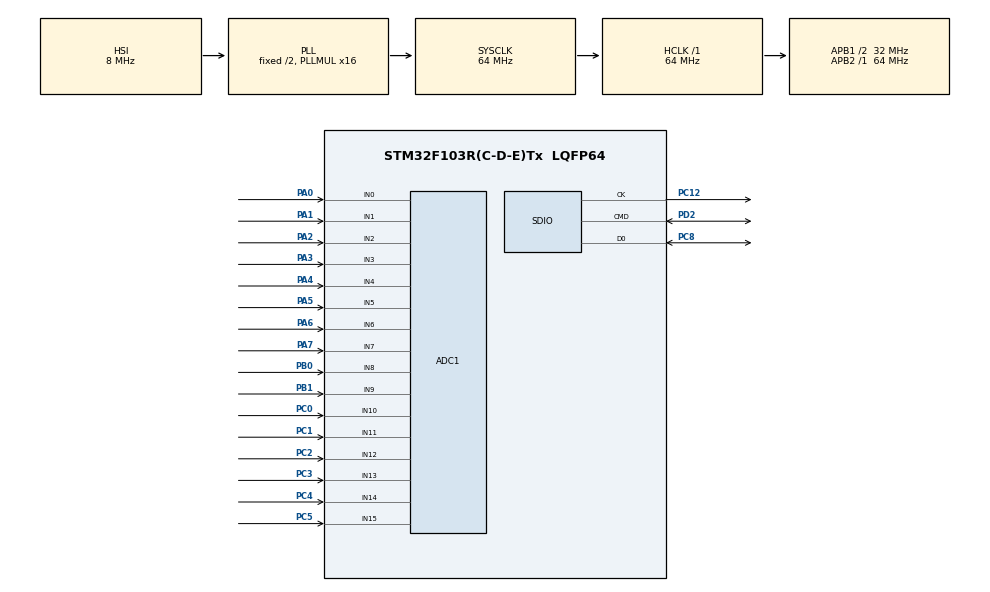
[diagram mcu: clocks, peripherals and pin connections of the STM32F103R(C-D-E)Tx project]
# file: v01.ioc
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ADC1.Channel-0\#ChannelRegularConversion=ADC_CHANNEL_0
ADC1.Channel-10\#ChannelRegularConversion=ADC_CHANNEL_6
ADC1.Channel-11\#ChannelRegularConversion=ADC_CHANNEL_7
ADC1.Channel-12\#ChannelRegularConversion=ADC_CHANNEL_8
ADC1.Channel-13\#ChannelRegularConversion=ADC_CHANNEL_9
ADC1.Channel-14\#ChannelRegularConversion=ADC_CHANNEL_10
ADC1.Channel-15\#ChannelRegularConversion=ADC_CHANNEL_11
ADC1.Channel-16\#ChannelRegularConversion=ADC_CHANNEL_12
ADC1.Channel-17\#ChannelRegularConversion=ADC_CHANNEL_13
ADC1.Channel-18\#ChannelRegularConversion=ADC_CHANNEL_14
ADC1.Channel-19\#ChannelRegularConversion=ADC_CHANNEL_15
ADC1.Channel-5\#ChannelRegularConversion=ADC_CHANNEL_1
ADC1.Channel-6\#ChannelRegularConversion=ADC_CHANNEL_2
ADC1.Channel-7\#ChannelRegularConversion=ADC_CHANNEL_3
ADC1.Channel-8\#ChannelRegularConversion=ADC_CHANNEL_4
ADC1.Channel-9\#ChannelRegularConversion=ADC_CHANNEL_5
ADC1.ContinuousConvMode=ENABLE
ADC1.InjNumberOfConversion=0
ADC1.NbrOfConversion=16
ADC1.NbrOfConversionFlag=1
ADC1.Rank-0\#ChannelRegularConversion=1
ADC1.Rank-10\#ChannelRegularConversion=7
ADC1.Rank-11\#ChannelRegularConversion=8
ADC1.Rank-12\#ChannelRegularConversion=9
ADC1.Rank-13\#ChannelRegularConversion=10
ADC1.Rank-14\#ChannelRegularConversion=11
ADC1.Rank-15\#ChannelRegularConversion=12
ADC1.Rank-16\#ChannelRegularConversion=13
ADC1.Rank-17\#ChannelRegularConversion=14
ADC1.Rank-18\#ChannelRegularConversion=15
ADC1.Rank-19\#ChannelRegularConversion=16
ADC1.Rank-5\#ChannelRegularConversion=2
ADC1.Rank-6\#ChannelRegularConversion=3
ADC1.Rank-7\#ChannelRegularConversion=4
ADC1.Rank-8\#ChannelRegularConversion=5
ADC1.Rank-9\#ChannelRegularConversion=6
ADC1.SamplingTime-0\#ChannelRegularConversion=ADC_SAMPLETIME_1CYCLE_5
ADC1.SamplingTime-10\#ChannelRegularConversion=ADC_SAMPLETIME_1CYCLE_5
ADC1.SamplingTime-11\#ChannelRegularConversion=ADC_SAMPLETIME_1CYCLE_5
ADC1.SamplingTime-12\#ChannelRegularConversion=ADC_SAMPLETIME_1CYCLE_5
ADC1.SamplingTime-13\#ChannelRegularConversion=ADC_SAMPLETIME_1CYCLE_5
ADC1.SamplingTime-14\#ChannelRegularConversion=ADC_SAMPLETIME_1CYCLE_5
ADC1.SamplingTime-15\#ChannelRegularConversion=ADC_SAMPLETIME_1CYCLE_5
ADC1.SamplingTime-16\#ChannelRegularConversion=ADC_SAMPLETIME_1CYCLE_5
ADC1.SamplingTime-17\#ChannelRegularConversion=ADC_SAMPLETIME_1CYCLE_5
ADC1.SamplingTime-18\#ChannelRegularConversion=ADC_SAMPLETIME_1CYCLE_5
ADC1.SamplingTime-19\#ChannelRegularConversion=ADC_SAMPLETIME_1CYCLE_5
ADC1.SamplingTime-5\#ChannelRegularConversion=ADC_SAMPLETIME_1CYCLE_5
ADC1.SamplingTime-6\#ChannelRegularConversion=ADC_SAMPLETIME_1CYCLE_5
ADC1.SamplingTime-7\#ChannelRegularConversion=ADC_SAMPLETIME_1CYCLE_5
ADC1.SamplingTime-8\#ChannelRegularConversion=ADC_SAMPLETIME_1CYCLE_5
ADC1.SamplingTime-9\#ChannelRegularConversion=ADC_SAMPLETIME_1CYCLE_5
ADC1.master=1
Dma.ADC1.0.Direction=DMA_PERIPH_TO_MEMORY
Dma.ADC1.0.Instance=DMA1_Channel1
Dma.ADC1.0.MemDataAlignment=DMA_MDATAALIGN_HALFWORD
Dma.ADC1.0.MemInc=DMA_MINC_ENABLE
Dma.ADC1.0.Mode=DMA_CIRCULAR
Dma.ADC1.0.PeriphDataAlignment=DMA_PDATAALIGN_HALFWORD
Dma.ADC1.0.PeriphInc=DMA_PINC_DISABLE
Dma.ADC1.0.Priority=DMA_PRIORITY_LOW
Dma.Request0=ADC1
Mcu.Family=STM32F1
Mcu.Name=STM32F103R(C-D-E)Tx
Mcu.Package=LQFP64
NVIC.DMA1_Channel1_IRQn=true\:0\:0\:false
NVIC.PriorityGroup=NVIC_PRIORITYGROUP_4
PA0-WKUP.Signal=ADCx_IN0
PA1.Signal=ADCx_IN1
PA13.Mode=Serial_Wire
PA13.Signal=SYS_JTMS-SWDIO
PA14.Mode=Serial_Wire
PA14.Signal=SYS_JTCK-SWCLK
PA2.Signal=ADCx_IN2
PA3.Signal=ADCx_IN3
PA4.Signal=ADCx_IN4
PA5.Signal=ADCx_IN5
PA6.Signal=ADCx_IN6
PA7.Signal=ADCx_IN7
PB0.Signal=ADCx_IN8
PB1.Signal=ADCx_IN9
PC0.Signal=ADCx_IN10
PC1.Signal=ADCx_IN11
PC12.Mode=SD_1_bit
PC12.Signal=SDIO_CK
PC2.Signal=ADCx_IN12
PC3.Signal=ADCx_IN13
PC4.Signal=ADCx_IN14
PC5.Signal=ADCx_IN15
PC8.Mode=SD_1_bit
PC8.Signal=SDIO_D0
PD2.Mode=SD_1_bit
PD2.Signal=SDIO_CMD
ProjectManager.TargetToolchain=SW4STM32
RCC.ADCPresc=RCC_ADCPCLK2_DIV8
RCC.AHBFreq_Value=64000000
RCC.APB1CLKDivider=RCC_HCLK_DIV2
RCC.APB1Freq_Value=32000000
RCC.APB1TimFreq_Value=64000000
RCC.APB2Freq_Value=64000000
RCC.APB2TimFreq_Value=64000000
RCC.HCLKFreq_Value=64000000
RCC.PLLMUL=RCC_PLL_MUL16
RCC.SYSCLKFreq_VALUE=64000000
RCC.SYSCLKSource=RCC_SYSCLKSOURCE_PLLCLK
RCC.USBFreq_Value=64000000
SDIO.BusWide=SDIO_BUS_WIDE_1B
SDIO.ClockDiv=2
SH.ADCx_IN0.0=ADC1_IN0,IN0
SH.ADCx_IN1.0=ADC1_IN1,IN1
SH.ADCx_IN10.0=ADC1_IN10,IN10
SH.ADCx_IN11.0=ADC1_IN11,IN11
SH.ADCx_IN12.0=ADC1_IN12,IN12
SH.ADCx_IN13.0=ADC1_IN13,IN13
SH.ADCx_IN14.0=ADC1_IN14,IN14
SH.ADCx_IN15.0=ADC1_IN15,IN15
SH.ADCx_IN2.0=ADC1_IN2,IN2
SH.ADCx_IN3.0=ADC1_IN3,IN3
SH.ADCx_IN4.0=ADC1_IN4,IN4
SH.ADCx_IN5.0=ADC1_IN5,IN5
SH.ADCx_IN6.0=ADC1_IN6,IN6
SH.ADCx_IN7.0=ADC1_IN7,IN7
SH.ADCx_IN8.0=ADC1_IN8,IN8
SH.ADCx_IN9.0=ADC1_IN9,IN9
board=v01

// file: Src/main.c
/**
  ******************************************************************************
  * File Name          : main.c
  * Description        : Main program body
  ******************************************************************************
  *
  * COPYRIGHT(c) 2015 STMicroelectronics
  *
  * Redistribution and use in source and binary forms, with or without modification,
  * are permitted provided that the following conditions are met:
  *   1. Redistributions of source code must retain the above copyright notice,
  *      this list of conditions and the following disclaimer.
  *   2. Redistributions in binary form must reproduce the above copyright notice,
  *      this list of conditions and the following disclaimer in the documentation
  *      and/or other materials provided with the distribution.
  *   3. Neither the name of STMicroelectronics nor the names of its contributors
  *      may be used to endorse or promote products derived from this software
  *      without specific prior written permission.
  *
  * THIS SOFTWARE IS PROVIDED BY THE COPYRIGHT HOLDERS AND CONTRIBUTORS "AS IS"
  * AND ANY EXPRESS OR IMPLIED WARRANTIES, INCLUDING, BUT NOT LIMITED TO, THE
  * IMPLIED WARRANTIES OF MERCHANTABILITY AND FITNESS FOR A PARTICULAR PURPOSE ARE
  * DISCLAIMED. IN NO EVENT SHALL THE COPYRIGHT HOLDER OR CONTRIBUTORS BE LIABLE
  * FOR ANY DIRECT, INDIRECT, INCIDENTAL, SPECIAL, EXEMPLARY, OR CONSEQUENTIAL
  * DAMAGES (INCLUDING, BUT NOT LIMITED TO, PROCUREMENT OF SUBSTITUTE GOODS OR
  * SERVICES; LOSS OF USE, DATA, OR PROFITS; OR BUSINESS INTERRUPTION) HOWEVER
  * CAUSED AND ON ANY THEORY OF LIABILITY, WHETHER IN CONTRACT, STRICT LIABILITY,
  * OR TORT (INCLUDING NEGLIGENCE OR OTHERWISE) ARISING IN ANY WAY OUT OF THE USE
  * OF THIS SOFTWARE, EVEN IF ADVISED OF THE POSSIBILITY OF SUCH DAMAGE.
  *
  ******************************************************************************
  */
#include "stm32f1xx_hal.h"

ADC_HandleTypeDef hadc1;
DMA_HandleTypeDef hdma_adc1;

SD_HandleTypeDef hsd;
HAL_SD_CardInfoTypedef SDCardInfo;

/* USER CODE BEGIN PV */
/* Private variables ---------------------------------------------------------*/
uint16_t convval[256];
uint16_t testval[256];
uint64_t address=0;
/* USER CODE END PV */

void SystemClock_Config(void);
static void MX_GPIO_Init(void);
static void MX_DMA_Init(void);
static void MX_ADC1_Init(void);
static void MX_SDIO_SD_Init(void);

/* USER CODE BEGIN PFP */
/* Private function prototypes -----------------------------------------------*/

/* USER CODE END PFP */

int main(void)
{

  /* MCU Configuration----------------------------------------------------------*/

  /* Reset of all peripherals, Initializes the Flash interface and the Systick. */
  HAL_Init();

  /* Configure the system clock */
  SystemClock_Config();

  /* Initialize all configured peripherals */
  MX_GPIO_Init();
  MX_DMA_Init();
  MX_ADC1_Init();
  MX_SDIO_SD_Init();

  /* USER CODE BEGIN 2 */
//  for (int k=0; k<254;k++){
//testval[k]=0x12345678;
//convval[k]=0;
//}
if ((HAL_ADC_Start_DMA(&hadc1, (uint32_t *)convval, 512)) != HAL_OK) {

while(1);
    }
  /* USER CODE END 2 */

  /* Infinite loop */
  while (1)
  {

  /* USER CODE BEGIN 3 */
    HAL_SD_WriteBlocks(&hsd, (uint32_t *)convval, address, 512, 1);
	address = address + 512;
	for (int i=0; i< 1000; i++);
  }
  /* USER CODE END 3 */

}

/** System Clock Configuration
*/
void SystemClock_Config(void)
{

  RCC_OscInitTypeDef RCC_OscInitStruct;
  RCC_ClkInitTypeDef RCC_ClkInitStruct;
  RCC_PeriphCLKInitTypeDef PeriphClkInit;

  RCC_OscInitStruct.OscillatorType = RCC_OSCILLATORTYPE_HSI;
  RCC_OscInitStruct.HSIState = RCC_HSI_ON;
  RCC_OscInitStruct.HSICalibrationValue = 16;
  RCC_OscInitStruct.PLL.PLLState = RCC_PLL_ON;
  RCC_OscInitStruct.PLL.PLLSource = RCC_PLLSOURCE_HSI_DIV2;
  RCC_OscInitStruct.PLL.PLLMUL = RCC_PLL_MUL16;
  HAL_RCC_OscConfig(&RCC_OscInitStruct);

  RCC_ClkInitStruct.ClockType = RCC_CLOCKTYPE_SYSCLK|RCC_CLOCKTYPE_PCLK1;
  RCC_ClkInitStruct.SYSCLKSource = RCC_SYSCLKSOURCE_PLLCLK;
  RCC_ClkInitStruct.AHBCLKDivider = RCC_SYSCLK_DIV1;
  RCC_ClkInitStruct.APB1CLKDivider = RCC_HCLK_DIV2;
  RCC_ClkInitStruct.APB2CLKDivider = RCC_HCLK_DIV1;
  HAL_RCC_ClockConfig(&RCC_ClkInitStruct, FLASH_LATENCY_2);

  PeriphClkInit.PeriphClockSelection = RCC_PERIPHCLK_ADC;
  PeriphClkInit.AdcClockSelection = RCC_ADCPCLK2_DIV8;
  HAL_RCCEx_PeriphCLKConfig(&PeriphClkInit);

  HAL_SYSTICK_Config(HAL_RCC_GetHCLKFreq()/1000);

  HAL_SYSTICK_CLKSourceConfig(SYSTICK_CLKSOURCE_HCLK);

}

/* ADC1 init function */
void MX_ADC1_Init(void)
{

  ADC_ChannelConfTypeDef sConfig;

    /**Common config
    */
  hadc1.Instance = ADC1;
  hadc1.Init.ScanConvMode = ADC_SCAN_ENABLE;
  hadc1.Init.ContinuousConvMode = ENABLE;
  hadc1.Init.DiscontinuousConvMode = DISABLE;
  hadc1.Init.ExternalTrigConv = ADC_SOFTWARE_START;
  hadc1.Init.DataAlign = ADC_DATAALIGN_RIGHT;
  hadc1.Init.NbrOfConversion = 16;
  HAL_ADC_Init(&hadc1);

    /**Configure Regular Channel
    */
  sConfig.Channel = ADC_CHANNEL_0;
  sConfig.Rank = 1;
  sConfig.SamplingTime = ADC_SAMPLETIME_1CYCLE_5;
  HAL_ADC_ConfigChannel(&hadc1, &sConfig);

    /**Configure Regular Channel
    */
  sConfig.Channel = ADC_CHANNEL_1;
  sConfig.Rank = 2;
  HAL_ADC_ConfigChannel(&hadc1, &sConfig);

    /**Configure Regular Channel
    */
  sConfig.Channel = ADC_CHANNEL_2;
  sConfig.Rank = 3;
  HAL_ADC_ConfigChannel(&hadc1, &sConfig);

    /**Configure Regular Channel
    */
  sConfig.Channel = ADC_CHANNEL_3;
  sConfig.Rank = 4;
  HAL_ADC_ConfigChannel(&hadc1, &sConfig);

    /**Configure Regular Channel
    */
  sConfig.Channel = ADC_CHANNEL_4;
  sConfig.Rank = 5;
  HAL_ADC_ConfigChannel(&hadc1, &sConfig);

    /**Configure Regular Channel
    */
  sConfig.Channel = ADC_CHANNEL_5;
  sConfig.Rank = 6;
  HAL_ADC_ConfigChannel(&hadc1, &sConfig);

    /**Configure Regular Channel
    */
  sConfig.Channel = ADC_CHANNEL_6;
  sConfig.Rank = 7;
  HAL_ADC_ConfigChannel(&hadc1, &sConfig);

    /**Configure Regular Channel
    */
  sConfig.Channel = ADC_CHANNEL_7;
  sConfig.Rank = 8;
  HAL_ADC_ConfigChannel(&hadc1, &sConfig);

    /**Configure Regular Channel
    */
  sConfig.Channel = ADC_CHANNEL_8;
  sConfig.Rank = 9;
  HAL_ADC_ConfigChannel(&hadc1, &sConfig);

    /**Configure Regular Channel
    */
  sConfig.Channel = ADC_CHANNEL_9;
  sConfig.Rank = 10;
  HAL_ADC_ConfigChannel(&hadc1, &sConfig);

    /**Configure Regular Channel
    */
  sConfig.Channel = ADC_CHANNEL_10;
  sConfig.Rank = 11;
  HAL_ADC_ConfigChannel(&hadc1, &sConfig);

    /**Configure Regular Channel
    */
  sConfig.Channel = ADC_CHANNEL_11;
  sConfig.Rank = 12;
  HAL_ADC_ConfigChannel(&hadc1, &sConfig);

    /**Configure Regular Channel
    */
  sConfig.Channel = ADC_CHANNEL_12;
  sConfig.Rank = 13;
  HAL_ADC_ConfigChannel(&hadc1, &sConfig);

    /**Configure Regular Channel
    */
  sConfig.Channel = ADC_CHANNEL_13;
  sConfig.Rank = 14;
  HAL_ADC_ConfigChannel(&hadc1, &sConfig);

    /**Configure Regular Channel
    */
  sConfig.Channel = ADC_CHANNEL_14;
  sConfig.Rank = 15;
  HAL_ADC_ConfigChannel(&hadc1, &sConfig);

    /**Configure Regular Channel
    */
  sConfig.Channel = ADC_CHANNEL_15;
  sConfig.Rank = 16;
  HAL_ADC_ConfigChannel(&hadc1, &sConfig);

}

/* SDIO init function */
void MX_SDIO_SD_Init(void)
{

  hsd.Instance = SDIO;
  hsd.Init.ClockEdge = SDIO_CLOCK_EDGE_RISING;
  hsd.Init.ClockBypass = SDIO_CLOCK_BYPASS_DISABLE;
  hsd.Init.ClockPowerSave = SDIO_CLOCK_POWER_SAVE_DISABLE;
  hsd.Init.BusWide = SDIO_BUS_WIDE_1B;
  hsd.Init.HardwareFlowControl = SDIO_HARDWARE_FLOW_CONTROL_DISABLE;
  hsd.Init.ClockDiv = 2;
  HAL_SD_Init(&hsd, &SDCardInfo);

}

void MX_DMA_Init(void)
{
  /* DMA controller clock enable */
  __HAL_RCC_DMA1_CLK_ENABLE();

  /* DMA interrupt init */
  HAL_NVIC_SetPriority(DMA1_Channel1_IRQn, 0, 0);
  HAL_NVIC_EnableIRQ(DMA1_Channel1_IRQn);

}

/** Configure pins as
        * Analog
        * Input
        * Output
        * EVENT_OUT
        * EXTI
*/
void MX_GPIO_Init(void)
{

  /* GPIO Ports Clock Enable */
  __GPIOC_CLK_ENABLE();
  __GPIOA_CLK_ENABLE();
  __GPIOB_CLK_ENABLE();
  __GPIOD_CLK_ENABLE();

}

/************************ (C) COPYRIGHT STMicroelectronics *****END OF FILE****/
